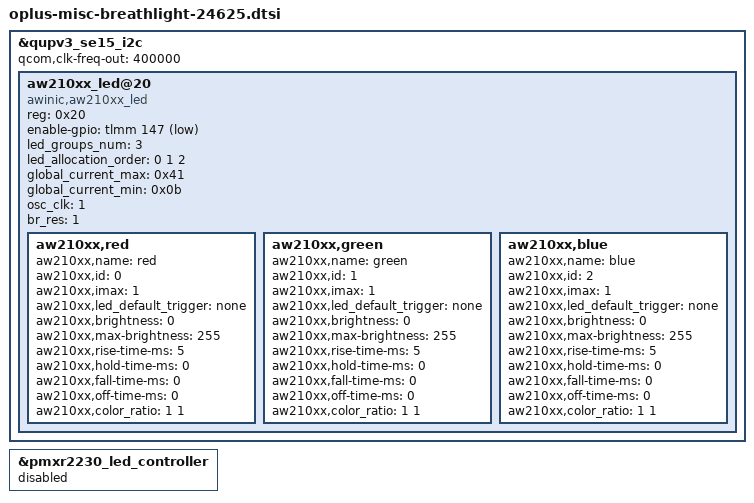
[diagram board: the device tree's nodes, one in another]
&qupv3_se15_i2c {
	status = "ok";
	qcom,clk-freq-out = <400000>;

	aw210xx_led@20 {
		compatible = "awinic,aw210xx_led";
		reg = <0x20>;

		/* Power Config */
		enable-gpio = <&tlmm 147 0x1>;
		//vbled-enable-gpio = <&tlmm 176 0x1>;
		//vbled-supply = <&L13B>;
		//vbled_volt = <3300000>;

		led_groups_num = <3>;
		led_allocation_order = <0 1 2>;
		global_current_max = <0x41>;
		global_current_min = <0x0b>;
		osc_clk = <1>;
		br_res = <1>;
		status = "okay";

		aw210xx,red {
			aw210xx,name = "red";
			aw210xx,id = <0>;
			aw210xx,imax = <1>;
			aw210xx,led_default_trigger = "none";
			aw210xx,brightness = <0>;
			aw210xx,max-brightness = <255>;
			aw210xx,rise-time-ms = <5>;
			aw210xx,hold-time-ms = <0>;
			aw210xx,fall-time-ms = <0>;
			aw210xx,off-time-ms = <0>;
			aw210xx,color_ratio = <1 1>;
		};
		aw210xx,green {
			aw210xx,name = "green";
			aw210xx,id = <1>;
			aw210xx,imax = <1>;
			aw210xx,led_default_trigger = "none";
			aw210xx,brightness = <0>;
			aw210xx,max-brightness = <255>;
			aw210xx,rise-time-ms = <5>;
			aw210xx,hold-time-ms = <0>;
			aw210xx,fall-time-ms = <0>;
			aw210xx,off-time-ms = <0>;
			aw210xx,color_ratio = <1 1>;
		};
		aw210xx,blue {
			aw210xx,name = "blue";
			aw210xx,id = <2>;
			aw210xx,imax = <1>;
			aw210xx,led_default_trigger = "none";
			aw210xx,brightness = <0>;
			aw210xx,max-brightness = <255>;
			aw210xx,rise-time-ms = <5>;
			aw210xx,hold-time-ms = <0>;
			aw210xx,fall-time-ms = <0>;
			aw210xx,off-time-ms = <0>;
			aw210xx,color_ratio = <1 1>;
		};
	};
};

&pmxr2230_led_controller {
	status = "disabled";
};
